# ATSAMD20E15BU device description
Architecture: CORTEX-M0PLUS; Family: SAMD; Series: SAMD20
Registers are 8-bit, read-write, reset 0x0 unless marked. A register's access mark holds for its fields unless they carry their own. Offsets are from the block's base; [hi:lo] are bit positions; {n}, {i} and the like mark numbered series; 'fields as' and 'values as' point back to an identical list.

## DSU — Device Service Unit
Instances: DSU 0x41002000
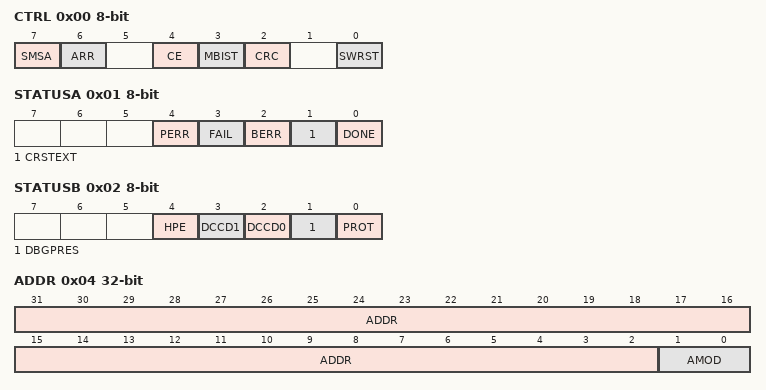
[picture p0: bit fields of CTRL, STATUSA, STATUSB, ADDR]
0x00 CTRL wo — Control
  [7] SMSA — Start Memory Stream Access
  [6] ARR — Auxiliary Row Read
  [4] CE — Chip-Erase
  [3] MBIST — Memory built-in self-test
  [2] CRC — 32-bit Cyclic Redundancy Code
  [0] SWRST — Software Reset
0x01 STATUSA
  [4] PERR — Protection Error
  [3] FAIL — Failure
  [2] BERR — Bus Error
  [1] CRSTEXT — CPU Reset Phase Extension
  [0] DONE
0x02 STATUSB ro
  [4] HPE — Hot-Plugging Enable
  [3] DCCD1 — Debug Communication Channel 1 Dirty
  [2] DCCD0 — Debug Communication Channel 0 Dirty
  [1] DBGPRES — Debugger Present
  [0] PROT — Protected
0x04 ADDR 32-bit — Address
  [31:2] ADDR — Address
  [1:0] AMOD — Access Mode
0x08 LENGTH 32-bit
  [31:2] LENGTH
0x0C DATA 32-bit
{0x10+4i} DCC[{i}] (i=0..1) 32-bit — Debug Communication Channel n
  [31:0] DATA
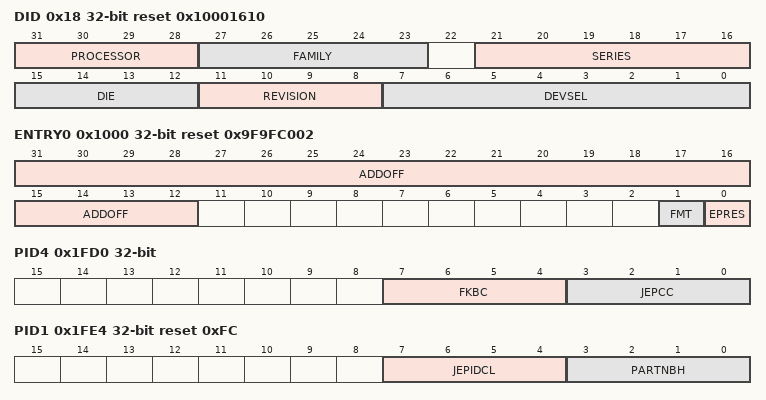
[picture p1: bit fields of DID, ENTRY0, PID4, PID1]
0x18 DID 32-bit ro reset 0x10001610 — Device Identification
  [31:28] PROCESSOR
    0=Cortex-M0; 1=Cortex-M0+; 2=Cortex-M3; 3=Cortex-M4
  [27:23] FAMILY
    0=General purpose microcontroller; 1=PicoPower
  [21:16] SERIES
    0=Cortex-M0+ processor, basic feature set; 1=Cortex-M0+ processor, USB
  [15:12] DIE — Die Number
  [11:8] REVISION — Revision Number
  [7:0] DEVSEL — Device Select
{0xF0+4i} DCFG[{i}] (i=0..1) 32-bit — Device Configuration
0x1000 ENTRY0 32-bit ro reset 0x9F9FC002 — Coresight ROM Table Entry 0
  [31:12] ADDOFF — Address Offset
  [1] FMT — Format
  [0] EPRES — Entry Present
0x1004 ENTRY1 32-bit ro — Coresight ROM Table Entry 1
0x1008 END 32-bit ro — Coresight ROM Table End
  [31:0] END — End Marker
0x1FCC MEMTYPE 32-bit ro — Coresight ROM Table Memory Type
  [0] SMEMP — System Memory Present
0x1FD0 PID4 32-bit ro — Peripheral Identification 4
  [7:4] FKBC — 4KB count
  [3:0] JEPCC — JEP-106 Continuation Code
{0x1FC0+4i} PID{i} 32-bit ro (i=5..7) — Peripheral Identification {i}
0x1FE0 PID0 32-bit ro reset 0xD0 — Peripheral Identification 0
  [7:0] PARTNBL — Part Number Low
0x1FE4 PID1 32-bit ro reset 0xFC — Peripheral Identification 1
  [7:4] JEPIDCL — Low part of the JEP-106 Identity Code
  [3:0] PARTNBH — Part Number High
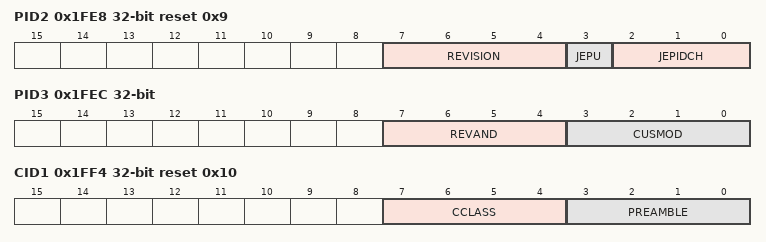
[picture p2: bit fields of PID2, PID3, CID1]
0x1FE8 PID2 32-bit ro reset 0x9 — Peripheral Identification 2
  [7:4] REVISION — Revision Number
  [3] JEPU — JEP-106 Identity Code is used
  [2:0] JEPIDCH — JEP-106 Identity Code High
0x1FEC PID3 32-bit ro — Peripheral Identification 3
  [7:4] REVAND — Revision Number
  [3:0] CUSMOD — ARM CUSMOD
0x1FF0 CID0 32-bit ro reset 0xD — Component Identification 0
  [7:0] PREAMBLEB0 — Preamble Byte 0
0x1FF4 CID1 32-bit ro reset 0x10 — Component Identification 1
  [7:4] CCLASS — Component Class
  [3:0] PREAMBLE
0x1FF8 CID2 32-bit ro reset 0x5 — Component Identification 2
  [7:0] PREAMBLEB2 — Preamble Byte 2
0x1FFC CID3 32-bit ro reset 0xB1 — Component Identification 3
  [7:0] PREAMBLEB3 — Preamble Byte 3

## EIC — External Interrupt Controller
Instances: EIC 0x40001800
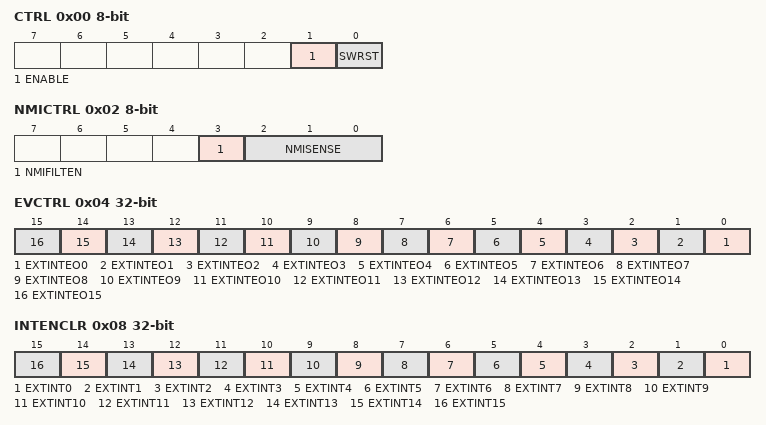
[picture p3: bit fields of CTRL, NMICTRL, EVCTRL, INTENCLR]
0x00 CTRL (WSYNC) — Control
  [1] ENABLE
  [0] SWRST — Software Reset
0x01 STATUS ro
  [7] SYNCBUSY — Synchronization Busy
0x02 NMICTRL — Non-Maskable Interrupt Control
  [3] NMIFILTEN — Non-Maskable Interrupt Filter Enable
  [2:0] NMISENSE — Non-Maskable Interrupt Sense
    0=NONE (No detection); 1=RISE (Rising-edge detection); 2=FALL (Falling-edge detection); 3=BOTH (Both-edges detection); 4=HIGH (High-level detection); 5=LOW (Low-level detection)
0x03 NMIFLAG (atomic clear) — Non-Maskable Interrupt Flag Status and Clear
  [0] NMI — Non-Maskable Interrupt
0x04 EVCTRL 32-bit — Event Control
  [n] EXTINTEO{n} (n=0..15) — External Interrupt {n} Event Output Enable
0x08 INTENCLR 32-bit (atomic clear) — Interrupt Enable Clear
  [n] EXTINT{n} (n=0..15) — External Interrupt {n} Enable
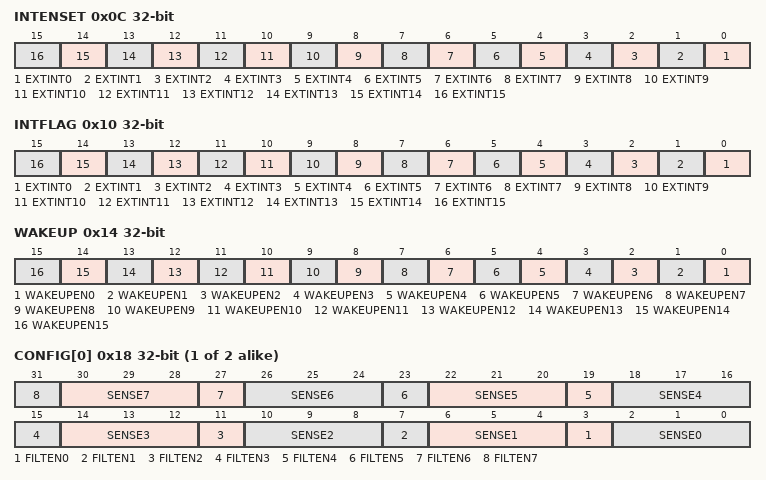
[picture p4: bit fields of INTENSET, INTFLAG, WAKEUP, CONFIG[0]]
0x0C INTENSET 32-bit (atomic set) — Interrupt Enable Set
  [n] EXTINT{n} (n=0..15) — External Interrupt {n} Enable
0x10 INTFLAG 32-bit (atomic clear) — Interrupt Flag Status and Clear
  [n] EXTINT{n} (n=0..15) — External Interrupt {n}
0x14 WAKEUP 32-bit — Wake-Up Enable
  [n] WAKEUPEN{n} (n=0..15) — External Interrupt {n} Wake-up Enable
{0x18+4i} CONFIG[{i}] (i=0..1) 32-bit — Configuration n
  [4n+3] FILTEN{n} (n=0..7) — Filter {n} Enable
  [4n+2:4n] SENSE{n} (n=1..7) — Input Sense {n} Configuration
    0=NONE (No detection); 1=RISE (Rising edge detection); 2=FALL (Falling edge detection); 3=BOTH (Both edges detection); 4=HIGH (High level detection); 5=LOW (Low level detection)
  [2:0] SENSE0 — Input Sense 0 Configuration
    values as NMICTRL.NMISENSE

## Notices in the file
Copyright (c) 2019 Microchip Technology Inc.
SPDX-License-Identifier: Apache-2.0
Licensed under the Apache License, Version 2.0 (the "License");
you may not use this file except in compliance with the License.
You may obtain a copy of the License at
http://www.apache.org/licenses/LICENSE-2.0
Unless required by applicable law or agreed to in writing, software
distributed under the License is distributed on an "AS IS" BASIS,
WITHOUT WARRANTIES OR CONDITIONS OF ANY KIND, either express or implied.
See the License for the specific language governing permissions and
limitations under the License.
